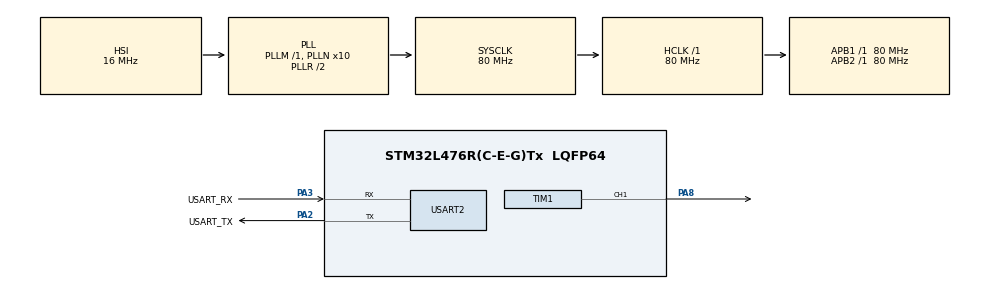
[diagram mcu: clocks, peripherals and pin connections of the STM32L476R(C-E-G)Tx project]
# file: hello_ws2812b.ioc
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Mcu.Family=STM32L4
PA2.GPIO_PuPd=GPIO_NOPULL
VP_SYS_VS_tim6.Mode=TIM6
RCC.CortexFreq_Value=80000000
NVIC.TIM6_DAC_IRQn=true\:0\:0\:false\:false\:true\:false\:false\:true
PH0-OSC_IN\ (PH0).Signal=RCC_OSC_IN
PA3.GPIO_PuPd=GPIO_NOPULL
PA2.GPIO_Speed=GPIO_SPEED_FREQ_VERY_HIGH
Dma.TIM1_CH1.0.MemDataAlignment=DMA_MDATAALIGN_HALFWORD
PC15-OSC32_OUT\ (PC15).Mode=LSE-External-Oscillator
PA3.GPIO_Speed=GPIO_SPEED_FREQ_VERY_HIGH
RCC.SYSCLKSource=RCC_SYSCLKSOURCE_PLLCLK
ProjectManager.StackSize=0x400
PB3\ (JTDO-TRACESWO).Signal=SYS_JTDO-SWO
PC14-OSC32_IN\ (PC14).Mode=LSE-External-Oscillator
VP_FREERTOS_VS_CMSIS_V2.Mode=CMSIS_V2
Dma.TIM1_CH1.0.MemInc=DMA_MINC_ENABLE
PA14\ (JTCK-SWCLK).Signal=SYS_JTCK-SWCLK
TIM1.Prescaler=0
RCC.HCLKFreq_Value=80000000
RCC.APB2TimFreq_Value=80000000
RCC.AHBFreq_Value=80000000
RCC.PREFETCH_ENABLE=1
RCC.HSE_VALUE=8000000
USART2.VirtualMode-Asynchronous=VM_ASYNC
TIM1.Channel-PWM\ Generation1\ CH1=TIM_CHANNEL_1
PA8.Signal=S_TIM1_CH1
Mcu.Package=LQFP64
NVIC.TimeBase=TIM6_DAC_IRQn
PA2.GPIO_Label=USART_TX
NVIC.TimeBaseIP=TIM6
RCC.APB1TimFreq_Value=80000000
TIM1.Period=100 - 1
PA13\ (JTMS-SWDIO).Signal=SYS_JTMS-SWDIO
Dma.Request0=TIM1_CH1
PA3.Signal=USART2_RX
PA2.GPIO_Mode=GPIO_MODE_AF_PP
RCC.MSI_VALUE=4000000
RCC.PLLSourceVirtual=RCC_PLLSOURCE_HSI
PA14\ (JTCK-SWCLK).Mode=Serial_Wire
FREERTOS.Tasks01=defaultTask,24,128,StartDefaultTask,Default,NULL,Dynamic,NULL,NULL
PC15-OSC32_OUT\ (PC15).Signal=RCC_OSC32_OUT
PA14\ (JTCK-SWCLK).GPIO_Label=TCK
PB3\ (JTDO-TRACESWO).GPIO_Label=SWO
Dma.TIM1_CH1.0.PeriphDataAlignment=DMA_PDATAALIGN_HALFWORD
Dma.TIM1_CH1.0.Priority=DMA_PRIORITY_LOW
PH1-OSC_OUT\ (PH1).Signal=RCC_OSC_OUT
Dma.TIM1_CH1.0.PeriphInc=DMA_PINC_DISABLE
PA3.Mode=Asynchronous
Dma.TIM1_CH1.0.Mode=DMA_NORMAL
SH.S_TIM1_CH1.0=TIM1_CH1,PWM Generation1 CH1
NVIC.DMA1_Channel2_IRQn=true\:5\:0\:false\:false\:true\:true\:false\:true
ProjectManager.TargetToolchain=STM32CubeIDE
PA3.GPIO_Mode=GPIO_MODE_AF_PP
RCC.USBFreq_Value=64000000
board=NUCLEO-L476RG
RCC.VCOOutputFreq_Value=160000000
RCC.APB2Freq_Value=80000000
PA13\ (JTMS-SWDIO).GPIO_Label=TMS
RCC.ADCFreq_Value=64000000
Mcu.Name=STM32L476R(C-E-G)Tx
PA2.Signal=USART2_TX
Dma.TIM1_CH1.0.Direction=DMA_MEMORY_TO_PERIPH
PA13\ (JTMS-SWDIO).Mode=Serial_Wire
RCC.SYSCLKFreq_VALUE=80000000
Dma.TIM1_CH1.0.Instance=DMA1_Channel2
PC14-OSC32_IN\ (PC14).Signal=RCC_OSC32_IN
ProjectManager.HeapSize=0x200
RCC.HSI_VALUE=16000000
NVIC.PriorityGroup=NVIC_PRIORITYGROUP_4
RCC.PLLN=10
PA2.Mode=Asynchronous
RCC.APB1Freq_Value=80000000
PA3.GPIO_Label=USART_RX

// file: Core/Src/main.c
/* USER CODE BEGIN Header */
/**
  ******************************************************************************
  * @file           : main.c
  * @brief          : Main program body
  ******************************************************************************
  * @attention
  *
  * <h2><center>&copy; Copyright (c) 2021 STMicroelectronics.
  * All rights reserved.</center></h2>
  *
  * This software component is licensed by ST under BSD 3-Clause license,
  * the "License"; You may not use this file except in compliance with the
  * License. You may obtain a copy of the License at:
  *                        opensource.org/licenses/BSD-3-Clause
  *
  ******************************************************************************
  */
/*
 * Credits To Controllers Tech
 *
 */
/* USER CODE END Header */
#include "main.h"
#include "cmsis_os.h"

/* USER CODE BEGIN Includes */
#include "math.h"
/* USER CODE END Includes */

/* USER CODE BEGIN PD */
#ifdef __GNUC__
	#define PUTCHAR_PROTOTYPE int __io_putchar(int ch)
#else
	#define PUTCHAR_PROTOTYPE int fputc(int ch, FILE *f)
#endif /* __GNUC__ */
/* USER CODE END PD */

TIM_HandleTypeDef htim1;
DMA_HandleTypeDef hdma_tim1_ch1;

UART_HandleTypeDef huart2;

/* Definitions for defaultTask */
osThreadId_t defaultTaskHandle;
const osThreadAttr_t defaultTask_attributes = {
  .name = "defaultTask",
  .stack_size = 128 * 4,
  .priority = (osPriority_t) osPriorityNormal,
};

void SystemClock_Config(void);
static void MX_GPIO_Init(void);
static void MX_DMA_Init(void);
static void MX_USART2_UART_Init(void);
static void MX_TIM1_Init(void);
void StartDefaultTask(void *argument);

/* USER CODE BEGIN 0 */
PUTCHAR_PROTOTYPE
{
	HAL_UART_Transmit(&huart2, (uint8_t *)&ch, 1, pdMS_TO_TICKS(100));
	return ch;
}

#define MAX_LED 8
#define USE_BRIGHTNESS 1

uint8_t LED_Data[MAX_LED][4];
uint8_t LED_Mod[MAX_LED][4]; // for brightness

volatile int datasentflag = 0;

void HAL_TIM_PWM_PulseFinishedCallback(TIM_HandleTypeDef *htim)
{
	// if htim == 1

	HAL_TIM_PWM_Stop_DMA(&htim1, TIM_CHANNEL_1);
	datasentflag = 1;
}

void Set_LED(int LEDnum, int Red, int Green, int Blue)
{
	LED_Data[LEDnum][0] = LEDnum;
	LED_Data[LEDnum][1] = Green;
	LED_Data[LEDnum][2] = Red;
	LED_Data[LEDnum][3] = Blue;

}

#define PI 3.14159625

void Set_Brightness(int brightness)
{
#if USE_BRIGHTNESS
	if (brightness > 45) brightness = 45;
	for (int i = 0; i < MAX_LED; i++)
	{
		LED_Mod[i][0] = LED_Data[i][0];
		for (int j = 1; j < 4; j++)
		{
			float angle = 90 - brightness;
			angle = angle*PI / 180;
			// [!] care for divide by 0!
			LED_Mod[i][j] = (LED_Data[i][j])/(tan(angle));
		}
	}
#endif
}

// uint16_t because half-word size chosen for DMA -> 16-bits
// [!] more memory efficient to do byte size
uint16_t pwmData[24*MAX_LED + 50];

void WS2812B_Send(void)
{
	uint32_t indx = 0;
	uint32_t color;

	for (int i = 0; i < MAX_LED; i++)
	{
		color = ((LED_Mod[i][1]<<16) | (LED_Mod[i][2]<<8) | (LED_Mod[i][3]));

		for (int i = 23; i >= 0; i--)
		{
			if (color & (1 << i))
			{
				pwmData[indx] = 64;
			}
			else
			{
				pwmData[indx] = 32;
			}
			indx++;
		}
	}

	for (int i = 0; i < 50; i++)
	{
		pwmData[indx] = 0;
		indx++;
	}

	HAL_TIM_PWM_Start_DMA(&htim1, TIM_CHANNEL_1, (uint32_t*)pwmData, indx);
	while (!datasentflag) {};
	datasentflag = 0;
}

void send(int Green, int Red, int Blue)
{
	uint32_t data = (Green << 16) | (Red << 8) | (Blue << 0);

	for (int i = 23; i >=0; i--)
	{
		if (data & (1<<i)) pwmData[i] = 64;
		else pwmData[i] = 32;
	}

	HAL_TIM_PWM_Start_DMA(&htim1, TIM_CHANNEL_1, (uint32_t *)pwmData, 24);
}
/* USER CODE END 0 */

int main(void)
{

  /* MCU Configuration--------------------------------------------------------*/

  /* Reset of all peripherals, Initializes the Flash interface and the Systick. */
  HAL_Init();

  /* Configure the system clock */
  SystemClock_Config();

  /* Initialize all configured peripherals */
  MX_GPIO_Init();
  MX_DMA_Init();
  MX_USART2_UART_Init();
  MX_TIM1_Init();

  /* Init scheduler */
  osKernelInitialize();

  /* Create the thread(s) */
  /* creation of defaultTask */
  defaultTaskHandle = osThreadNew(StartDefaultTask, NULL, &defaultTask_attributes);

  /* Start scheduler */
  osKernelStart();

  /* We should never get here as control is now taken by the scheduler */
  /* Infinite loop */
  while (1)
  {

  }
}

void SystemClock_Config(void)
{
  RCC_OscInitTypeDef RCC_OscInitStruct = {0};
  RCC_ClkInitTypeDef RCC_ClkInitStruct = {0};
  RCC_PeriphCLKInitTypeDef PeriphClkInit = {0};

  /** Initializes the RCC Oscillators according to the specified parameters
  * in the RCC_OscInitTypeDef structure.
  */
  RCC_OscInitStruct.OscillatorType = RCC_OSCILLATORTYPE_HSI;
  RCC_OscInitStruct.HSIState = RCC_HSI_ON;
  RCC_OscInitStruct.HSICalibrationValue = RCC_HSICALIBRATION_DEFAULT;
  RCC_OscInitStruct.PLL.PLLState = RCC_PLL_ON;
  RCC_OscInitStruct.PLL.PLLSource = RCC_PLLSOURCE_HSI;
  RCC_OscInitStruct.PLL.PLLM = 1;
  RCC_OscInitStruct.PLL.PLLN = 10;
  RCC_OscInitStruct.PLL.PLLP = RCC_PLLP_DIV7;
  RCC_OscInitStruct.PLL.PLLQ = RCC_PLLQ_DIV2;
  RCC_OscInitStruct.PLL.PLLR = RCC_PLLR_DIV2;
  if (HAL_RCC_OscConfig(&RCC_OscInitStruct) != HAL_OK)
  {
    Error_Handler();
  }
  /** Initializes the CPU, AHB and APB buses clocks
  */
  RCC_ClkInitStruct.ClockType = RCC_CLOCKTYPE_HCLK|RCC_CLOCKTYPE_SYSCLK
                              |RCC_CLOCKTYPE_PCLK1|RCC_CLOCKTYPE_PCLK2;
  RCC_ClkInitStruct.SYSCLKSource = RCC_SYSCLKSOURCE_PLLCLK;
  RCC_ClkInitStruct.AHBCLKDivider = RCC_SYSCLK_DIV1;
  RCC_ClkInitStruct.APB1CLKDivider = RCC_HCLK_DIV1;
  RCC_ClkInitStruct.APB2CLKDivider = RCC_HCLK_DIV1;

  if (HAL_RCC_ClockConfig(&RCC_ClkInitStruct, FLASH_LATENCY_4) != HAL_OK)
  {
    Error_Handler();
  }
  PeriphClkInit.PeriphClockSelection = RCC_PERIPHCLK_USART2;
  PeriphClkInit.Usart2ClockSelection = RCC_USART2CLKSOURCE_PCLK1;
  if (HAL_RCCEx_PeriphCLKConfig(&PeriphClkInit) != HAL_OK)
  {
    Error_Handler();
  }
  /** Configure the main internal regulator output voltage
  */
  if (HAL_PWREx_ControlVoltageScaling(PWR_REGULATOR_VOLTAGE_SCALE1) != HAL_OK)
  {
    Error_Handler();
  }
}

static void MX_TIM1_Init(void)
{

  TIM_MasterConfigTypeDef sMasterConfig = {0};
  TIM_OC_InitTypeDef sConfigOC = {0};
  TIM_BreakDeadTimeConfigTypeDef sBreakDeadTimeConfig = {0};

  htim1.Instance = TIM1;
  htim1.Init.Prescaler = 0;
  htim1.Init.CounterMode = TIM_COUNTERMODE_UP;
  htim1.Init.Period = 100 - 1;
  htim1.Init.ClockDivision = TIM_CLOCKDIVISION_DIV1;
  htim1.Init.RepetitionCounter = 0;
  htim1.Init.AutoReloadPreload = TIM_AUTORELOAD_PRELOAD_DISABLE;
  if (HAL_TIM_PWM_Init(&htim1) != HAL_OK)
  {
    Error_Handler();
  }
  sMasterConfig.MasterOutputTrigger = TIM_TRGO_RESET;
  sMasterConfig.MasterOutputTrigger2 = TIM_TRGO2_RESET;
  sMasterConfig.MasterSlaveMode = TIM_MASTERSLAVEMODE_DISABLE;
  if (HAL_TIMEx_MasterConfigSynchronization(&htim1, &sMasterConfig) != HAL_OK)
  {
    Error_Handler();
  }
  sConfigOC.OCMode = TIM_OCMODE_PWM1;
  sConfigOC.Pulse = 0;
  sConfigOC.OCPolarity = TIM_OCPOLARITY_HIGH;
  sConfigOC.OCNPolarity = TIM_OCNPOLARITY_HIGH;
  sConfigOC.OCFastMode = TIM_OCFAST_DISABLE;
  sConfigOC.OCIdleState = TIM_OCIDLESTATE_RESET;
  sConfigOC.OCNIdleState = TIM_OCNIDLESTATE_RESET;
  if (HAL_TIM_PWM_ConfigChannel(&htim1, &sConfigOC, TIM_CHANNEL_1) != HAL_OK)
  {
    Error_Handler();
  }
  sBreakDeadTimeConfig.OffStateRunMode = TIM_OSSR_DISABLE;
  sBreakDeadTimeConfig.OffStateIDLEMode = TIM_OSSI_DISABLE;
  sBreakDeadTimeConfig.LockLevel = TIM_LOCKLEVEL_OFF;
  sBreakDeadTimeConfig.DeadTime = 0;
  sBreakDeadTimeConfig.BreakState = TIM_BREAK_DISABLE;
  sBreakDeadTimeConfig.BreakPolarity = TIM_BREAKPOLARITY_HIGH;
  sBreakDeadTimeConfig.BreakFilter = 0;
  sBreakDeadTimeConfig.Break2State = TIM_BREAK2_DISABLE;
  sBreakDeadTimeConfig.Break2Polarity = TIM_BREAK2POLARITY_HIGH;
  sBreakDeadTimeConfig.Break2Filter = 0;
  sBreakDeadTimeConfig.AutomaticOutput = TIM_AUTOMATICOUTPUT_DISABLE;
  if (HAL_TIMEx_ConfigBreakDeadTime(&htim1, &sBreakDeadTimeConfig) != HAL_OK)
  {
    Error_Handler();
  }
  HAL_TIM_MspPostInit(&htim1);

}

static void MX_USART2_UART_Init(void)
{

  huart2.Instance = USART2;
  huart2.Init.BaudRate = 115200;
  huart2.Init.WordLength = UART_WORDLENGTH_8B;
  huart2.Init.StopBits = UART_STOPBITS_1;
  huart2.Init.Parity = UART_PARITY_NONE;
  huart2.Init.Mode = UART_MODE_TX_RX;
  huart2.Init.HwFlowCtl = UART_HWCONTROL_NONE;
  huart2.Init.OverSampling = UART_OVERSAMPLING_16;
  huart2.Init.OneBitSampling = UART_ONE_BIT_SAMPLE_DISABLE;
  huart2.AdvancedInit.AdvFeatureInit = UART_ADVFEATURE_NO_INIT;
  if (HAL_UART_Init(&huart2) != HAL_OK)
  {
    Error_Handler();
  }

}

static void MX_DMA_Init(void)
{

  /* DMA controller clock enable */
  __HAL_RCC_DMA1_CLK_ENABLE();

  /* DMA interrupt init */
  /* DMA1_Channel2_IRQn interrupt configuration */
  HAL_NVIC_SetPriority(DMA1_Channel2_IRQn, 5, 0);
  HAL_NVIC_EnableIRQ(DMA1_Channel2_IRQn);

}

static void MX_GPIO_Init(void)
{

  /* GPIO Ports Clock Enable */
  __HAL_RCC_GPIOC_CLK_ENABLE();
  __HAL_RCC_GPIOH_CLK_ENABLE();
  __HAL_RCC_GPIOA_CLK_ENABLE();
  __HAL_RCC_GPIOB_CLK_ENABLE();

}

void StartDefaultTask(void *argument)
{
  /* USER CODE BEGIN 5 */
  /* Infinite loop */
  for(;;)
  {
  	printf("Hello, world!\r\n");

  	//send(5, 255, 101);

  	Set_LED(0, 255, 0, 0);
  	Set_LED(1, 0, 255, 0);
  	Set_LED(2, 0, 0, 255);
  	Set_Brightness(1);
  	WS2812B_Send();

  	osDelay(1000);
  	Set_LED(0, 12, 52, 64);
  	Set_LED(1, 4, 235, 145);
  	Set_LED(2, 120, 120, 25);
  	Set_Brightness(1);
  	WS2812B_Send();

  	osDelay(1000);
  }
  /* USER CODE END 5 */
}

 /**
  * @brief  Period elapsed callback in non blocking mode
  * @note   This function is called  when TIM6 interrupt took place, inside
  * HAL_TIM_IRQHandler(). It makes a direct call to HAL_IncTick() to increment
  * a global variable "uwTick" used as application time base.
  * @param  htim : TIM handle
  * @retval None
  */
void HAL_TIM_PeriodElapsedCallback(TIM_HandleTypeDef *htim)
{
  if (htim->Instance == TIM6) {
    HAL_IncTick();
  }
}

void Error_Handler(void)
{
  __disable_irq();
  while (1)
  {
  }
}

/************************ (C) COPYRIGHT STMicroelectronics *****END OF FILE****/
